# LKS32MC08x register map
Vendor: Linko Ltd.; Series: LKS32MC08x; File version: 1.0
CPU: CM0 r1p0, little endian, MPU, no FPU, 3 interrupt priority bits
Registers are 32-bit, read-write, reset 0x0 unless marked. A register's access mark holds for its fields unless they carry their own. Offsets are from the block's base; [hi:lo] are bit positions; {n}, {i} and the like mark numbered series; 'fields as' and 'values as' point back to an identical list.

## MCPWM — MCPWM registers
Base 0x40011C00
0x00 MCPWM_TH00 (reset mask 0xFFFF) — MCPWM0 CH0 P 16-bit Signed Compare Threshold Value
0x04 MCPWM_TH01 (reset mask 0xFFFF) — MCPWM0 CH0 N 16-bit Signed Compare Threshold Value
0x08 MCPWM_TH10 (reset mask 0xFFFF) — MCPWM1 CH1 P 16-bit Signed Compare Threshold Value
0x0C MCPWM_TH11 (reset mask 0xFFFF) — MCPWM1 CH1 N 16-bit Signed Compare Threshold Value
0x10 MCPWM_TH20 (reset mask 0xFFFF) — MCPWM2 CH2 P 16-bit Signed Compare Threshold Value
0x14 MCPWM_TH21 (reset mask 0xFFFF) — MCPWM2 CH2 N 16-bit Signed Compare Threshold Value
0x18 MCPWM_TH30 (reset mask 0xFFFF) — MCPWM3 CH3 P 16-bit Signed Compare Threshold Value
0x1C MCPWM_TH31 (reset mask 0xFFFF) — MCPWM3 CH3 N 16-bit Signed Compare Threshold Value
{0x20+4i} MCPWM_TMR{i} (reset mask 0xFFFF) (i=0..3) — ADC Sample Timer, 16-bit Signed Compare Threshold Value {i}
0x30 MCPWM_TH (reset mask 0x7FFF) — MCPWM Base Counter 15-bit Unsigned Threshold Value
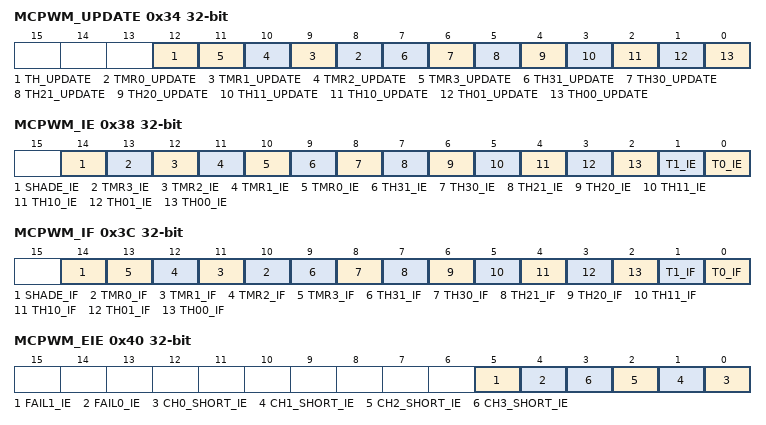
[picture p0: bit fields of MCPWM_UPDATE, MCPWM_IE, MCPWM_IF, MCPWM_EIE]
0x34 MCPWM_UPDATE wo — Mask Registers Manual Reload Configuration
  [12] TH_UPDATE — Write 1 to Trig TH Update Forcely
    0=Disabled (No Update); 1=Enabled (Trig TH Update)
  [n+8] TMR{n}_UPDATE (n=0..3) — Write 1 to Trig TMR{n} Update Forcely
    0=Disabled (No Update); 1=Enabled (Trig TMR{n} Update)
  [7] TH31_UPDATE — Write 1 to Trig TH31 Update Forcely
    0=Disabled (No Update); 1=Enabled (Trig TH31 Update)
  [6] TH30_UPDATE — Write 1 to Trig TH30 Update Forcely
    0=Disabled (No Update); 1=Enabled (Trig TH30 Update)
  [5] TH21_UPDATE — Write 1 to Trig TH21 Update Forcely
    0=Disabled (No Update); 1=Enabled (Trig TH21 Update)
  [4] TH20_UPDATE — Write 1 to Trig TH20 Update Forcely
    0=Disabled (No Update); 1=Enabled (Trig TH20 Update)
  [3] TH11_UPDATE — Write 1 to Trig TH11 Update Forcely
    0=Disabled (No Update); 1=Enabled (Trig TH11 Update)
  [2] TH10_UPDATE — Write 1 to Trig TH10 Update Forcely
    0=Disabled (No Update); 1=Enabled (Trig TH10 Update)
  [1] TH01_UPDATE — Write 1 to Trig TH01 Update Forcely
    0=Disabled (No Update); 1=Enabled (Trig TH01 Update)
  [0] TH00_UPDATE — Write 1 to Trig TH00 Update Forcely
    0=Disabled (No Update); 1=Enabled (Trig TH00 Update)
0x38 MCPWM_IE — Interrupt Sources Enable
  [14] SHADE_IE — Shade Register Update Interrupt Enable
    0=Disabled (Shade Register Event will not generate interrupt); 1=Enabled (Shade Register Event will generate interrupt)
  [13] TMR3_IE — Timer is equal to TMR3 Interrupt Enable
    0=Disabled (TMR3 Event will not generate interrupt); 1=Enabled (TMR3 Event will generate interrupt)
  [12] TMR2_IE — Timer is equal to TMR2 Interrupt
    0=Disabled (TMR2 Event will not generate interrupt); 1=Enabled (TMR2 Event will generate interrupt)
  [11] TMR1_IE — Timer is equal to TMR1 Interrupt
    0=Disabled (TMR1 Event will not generate interrupt); 1=Enabled (TMR1 Event will generate interrupt)
  [10] TMR0_IE — TMR0 Event,Timer is equal to TMR0 Interrupt
    0=Disabled (TMR0 Event will not generate interrupt); 1=Enabled (TMR0 Event will generate interrupt)
  [9] TH31_IE — Timer is equal to TH31 Interrupt
    0=Disabled (TH31 Event will not generate interrupt); 1=Enabled (TH31 Event will generate interrupt)
  [8] TH30_IE — TH30 Event,Timer is equal to TH30 Interrupt
    0=Disabled (TH30 Event will not generate interrupt); 1=Enabled (TH30 Event will generate interrupt)
  [7] TH21_IE — TH21 Event,Timer is equal to TH21 Interrupt
    0=Disabled (TH21 Event will not generate interrupt); 1=Enabled (TH21 Event will generate interrupt)
  [6] TH20_IE — Timer is equal to TH20 Interrupt
    0=Disabled (TH20 Event will not generate interrupt); 1=Enabled (TH20 Event will generate interrupt)
  [5] TH11_IE — TH11 Event,Timer is equal to TH11 Interrupt
    0=Disabled (TH11 Event will not generate interrupt); 1=Enabled (TH11 Event will generate interrupt)
  [4] TH10_IE — Timer is equal to TH10 Interrupt
    0=Disabled (TH10 Event will not generate interrupt); 1=Enabled (TH10 Event will generate interrupt)
  [3] TH01_IE — TH01 Event,Timer is equal to TH01 Interrupt
    0=Disabled (TH01 Event will not generate interrupt); 1=Enabled (TH01 Event will generate interrupt)
  [2] TH00_IE — Timer is equal to TH00 Interrupt
    0=Disabled (TH00 Event will not generate interrupt); 1=Enabled (TH00 Event will generate interrupt)
  [1] T1_IE — Timer is equal to 0 Interrupt
    0=Disabled (T1 Event will not generate interrupt); 1=Enabled (T1 Event will generate interrupt)
  [0] T0_IE — Timer Return to -TH Interrupt
    0=Disabled (T0 Event will not generate interrupt); 1=Enabled (T0 Event will generate interrupt)
0x3C MCPWM_IF — Interrupt Flags Write Clear
  [14] SHADE_IF — Shade Register Update Interrupt Flag
    0=Clear (Shade Register Interrupt Flag not set); 1=Set (Shade Register Interrupt Flag set)
  [n+10] TMR{n}_IF (n=0..3) — TMR{n} Interrupt Flag,Timer is equal to TMR{n}
    0=Clear (TMR{n} Interrupt Flag not set); 1=Set (TMR{n} Interrupt Flag set)
  [9] TH31_IF — TH31 Interrupt Flag,Timer is equal to TH31
    0=Clear (TH31 Interrupt Flag not set); 1=Set (TH31 Interrupt Flag set)
  [8] TH30_IF — TH30 Interrupt Flag,Timer is equal to TH30
    0=Clear (TH30 Interrupt Flag not set); 1=Set (TH30 Interrupt Flag set)
  [7] TH21_IF — TH21 Interrupt Flag,Timer is equal to TH21
    0=Clear (TH21 Interrupt Flag not set); 1=Set (TH21 Interrupt Flag set)
  [6] TH20_IF — TH20 Interrupt Flag,Timer is equal to TH20
    0=Clear (TH20 Interrupt Flag not set); 1=Set (TH20 Interrupt Flag set)
  [5] TH11_IF — TH11 Interrupt Flag,Timer is equal to TH11
    0=Clear (TH11 Interrupt Flag not set); 1=Set (TH11 Interrupt Flag set)
  [4] TH10_IF — TH10 Interrupt Flag,Timer is equal to TH10
    0=Clear (TH10 Interrupt Flag not set); 1=Set (TH10 Interrupt Flag set)
  [3] TH01_IF — TH01 Interrupt Flag,Timer is equal to TH01
    0=Clear (TH01 Interrupt Flag not set); 1=Set (TH01 Interrupt Flag set)
  [2] TH00_IF — TH00 Interrupt Flag,Timer is equal to TH00
    0=Clear (TH00 Interrupt Flag not set); 1=Set (TH00 Interrupt Flag set)
  [1] T1_IF — T1 Interrupt Flag,Timer Return to -TH
    0=Clear (T1 Interrupt Flag not set); 1=Set (T1 Interrupt Flag set)
  [0] T0_IF — T0 Interrupt Flag,Timer Return to -TH
    0=Clear (T0 Interrupt Flag not set); 1=Set (T0 Interrupt Flag set)
0x40 MCPWM_EIE — Error Interrupt Sources Enable
  [5] FAIL1_IE — FAIL1 Interrupt
    0=Disabled (FAIL1 will not generate interrupt); 1=Enabled (FAIL1 will generate interrupt)
  [4] FAIL0_IE — FAIL0 Interrupt
    0=Disabled (FAIL0 will not generate interrupt); 1=Enabled (FAIL0 will generate interrupt)
  [n] CH{n}_SHORT_IE (n=0..3) — CH{n} Short Interrupt
    0=Disabled (CH{n} Short will not generate interrupt); 1=Enabled (CH{n} Short will generate interrupt)
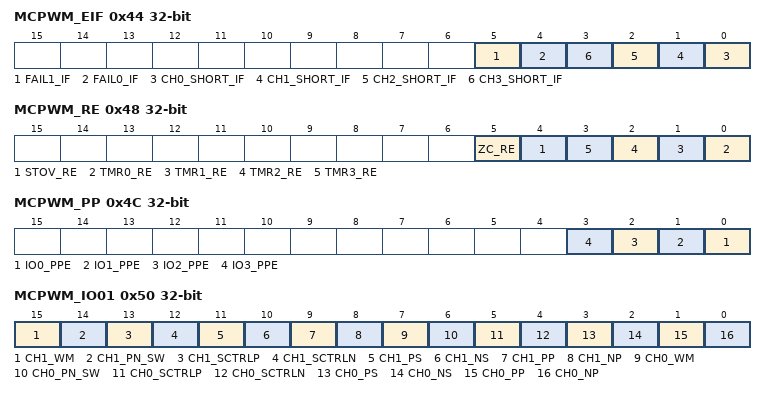
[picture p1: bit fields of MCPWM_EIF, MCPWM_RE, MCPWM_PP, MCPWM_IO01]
0x44 MCPWM_EIF — Error Interrupt Flags Write Clear
  [5] FAIL1_IF — FAIL1 Interrupt Flag
    0=Clear (FAIL1 flag not set); 1=Set (FAIL1 flag set)
  [4] FAIL0_IF — FAIL0 Interrupt Flag
    0=Clear (FAIL0 flag not set); 1=Set (FAIL0 flag set)
  [n] CH{n}_SHORT_IF (n=0..3) — CH{n} Short Interrupt Flag
    0=Clear (CH{n} Short flag not set); 1=Set (CH{n} Short flag set)
0x48 MCPWM_RE — DMA request enable
  [5] ZC_RE — Zero Crossing Event will request DMA or not
    0=Disabled (Zero Crossing Event DMA request is disabled); 1=Enabled (Zero Crossing Event DMA request is enabled)
  [4] STOV_RE — Counter Start Over Event will request DMA or not
    0=Disabled (Conter start over event DMA request is disabled); 1=Enabled (Conter start over event DMA request is enabled)
  [n] TMR{n}_RE (n=0..3) — ADC trigger {n} will request DMA or not
    0=Disabled (ADC trigger {n} DMA request is disabled); 1=Enabled (ADC trigger {n} DMA request is enabled)
0x4C MCPWM_PP — Push-Pull configuration
  [n] IO{n}_PPE (n=0..3) — IO{n} Push-Pull mode enable
    0=Disabled (IO{n} Push-Pull mode is disabled); 1=Enabled (IO{n} Push-Pull mode is enabled)
0x50 MCPWM_IO01 — Channel 0/1 Setting
  [15] CH1_WM — Channel_1 WorkMode
    0=CMP (Complement Mode); 1=Edge Mode
  [14] CH1_PN_SW — Channel_1 P/N Switch
    0=ORG (Not Switch); 1=SWAP (Switch)
  [13] CH1_SCTRLP — Channel_1 SoftCtrlP
    0=L (P set to 0); 1=H (P set to 1)
  [12] CH1_SCTRLN — Channel_1 SoftCtrlN
    0=L (N set to 0); 1=H (N set to 1)
  [11] CH1_PS — Channel_1 P Source
    0=TIMER (From Timer); 1=BIT13 (From Bit13)
  [10] CH1_NS — Channel_1 N Source
    0=TIMER (From Timer); 1=BIT12 (From Bit12)
  [9] CH1_PP — Channel_1 P Polarity
    0=Disabled (P Not Inverted); 1=Enabled (P Inverted)
  [8] CH1_NP — Channel_1 N Polarity
    0=Disabled (N Not Inverted); 1=Enabled (N Inverted)
  [7] CH0_WM — Channel_0 WorkMode
    0=CMP (Complement Mode); 1=Edge Mode
  [6] CH0_PN_SW — Channel_0 P/N Switch
    0=ORG (Not Switch); 1=SWAP (Switch)
  [5] CH0_SCTRLP — Channel_0 SoftCtrlP
    0=L (P set to 0); 1=H (P set to 1)
  [4] CH0_SCTRLN — Channel_0 SoftCtrlN
    0=L (N set to 0); 1=H (N set to 1)
  [3] CH0_PS — Channel_0 P Source
    0=TIMER (From Timer); 1=BIT13 (From Bit13)
  [2] CH0_NS — Channel_0 N Source
    0=TIMER (From Timer); 1=BIT12 (From Bit12)
  [1] CH0_PP — Channel_0 P Polarity
    0=Disabled (P Not Inverted); 1=Enabled (P Inverted)
  [0] CH0_NP — Channel_0 N Polarity
    0=Disabled (N Not Inverted); 1=Enabled (N Inverted)
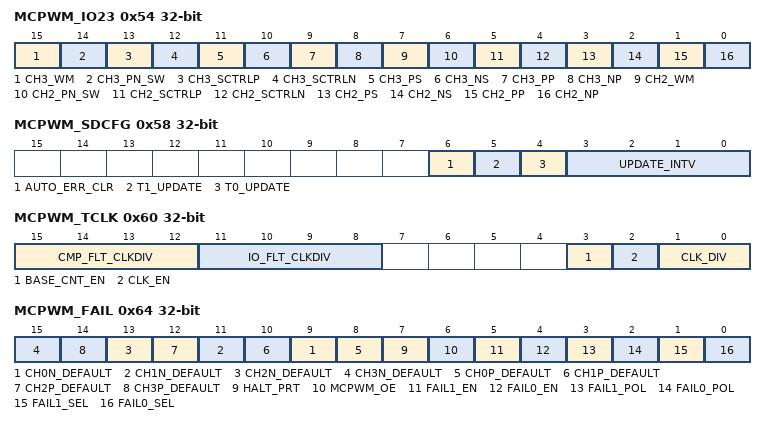
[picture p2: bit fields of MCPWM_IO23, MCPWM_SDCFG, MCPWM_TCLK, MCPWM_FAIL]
0x54 MCPWM_IO23 — Channel 2/3 Setting
  [15] CH3_WM — Channel_3 WorkMode
    0=CMP (Complement Mode); 1=Edge Mode
  [14] CH3_PN_SW — Channel_3 P/N Switch
    0=ORG (Not Switch); 1=SWAP (Switch)
  [13] CH3_SCTRLP — Channel_3 SoftCtrlP
    0=L (P set to 0); 1=H (P set to 1)
  [12] CH3_SCTRLN — Channel_3 SoftCtrlN
    0=L (N set to 0); 1=H (N set to 1)
  [11] CH3_PS — Channel_3 P Source
    0=TIMER (From Timer); 1=BIT13 (From Bit13)
  [10] CH3_NS — Channel_3 N Source
    0=TIMER (From Timer); 1=BIT12 (From Bit12)
  [9] CH3_PP — Channel_3 P Polarity
    0=Disabled (P Not Inverted); 1=Enabled (P Inverted)
  [8] CH3_NP — Channel_3 N Polarity
    0=Disabled (N Not Inverted); 1=Enabled (N Inverted)
  [7] CH2_WM — Channel_2 WorkMode
    0=CMP (Complement Mode); 1=Edge Mode
  [6] CH2_PN_SW — Channel_2 P/N Switch
    0=ORG (Not Switch); 1=SWAP (Switch)
  [5] CH2_SCTRLP — Channel_2 SoftCtrlP
    0=L (P set to 0); 1=H (P set to 1)
  [4] CH2_SCTRLN — Channel_2 SoftCtrlN
    0=L (N set to 0); 1=H (N set to 1)
  [3] CH2_PS — Channel_2 P Source
    0=TIMER (From Timer); 1=BIT13 (From Bit13)
  [2] CH2_NS — Channel_2 N Source
    0=TIMER (From Timer); 1=BIT12 (From Bit12)
  [1] CH2_PP — Channel_2 P Polarity
    0=Disabled (P Not Inverted); 1=Enabled (P Inverted)
  [0] CH2_NP — Channel_2 N Polarity
    0=Disabled (N Not Inverted); 1=Enabled (N Inverted)
0x58 MCPWM_SDCFG (reset mask 0x3F) — Mask Registers Reload Configuration
  [6] AUTO_ERR_CLR — Whether to clear MOE upon update events
    0=Disabled (Not clear); 1=Enabled (Clear)
  [5] T1_UPDATE — Update shadow registers @ T1 event
    0=Disabled (T1 Event will not update shadow registers); 1=Enabled (T1 Event will update shadow registers)
  [4] T0_UPDATE — Update shadow registers @ T0 event
    0=Disabled (T0 Event will not update shadow registers); 1=Enabled (T0 Event will update shadow registers)
  [3:0] UPDATE_INTV — Mask Registers Auto Update Interval, Range From 1 To 16. T1/T2 Events Can Accumulate Interval Source Register
    {v}=Value (The Total Number of T1 and T2 Event is {v+1}) (v=0..15)
0x60 MCPWM_TCLK — MCPWM Clock Configuration Register
  [15:12] CMP_FLT_CLKDIV — Clock Source is System Clock, Divide Range is 1 to 16
    {v}=Value (Divide by {v+1}) (v=0..15)
  [11:8] IO_FLT_CLKDIV — Clock Source is System Clock, Divide Range is 1 to 16
    {v}=Value (Divide by {v+1}) (v=0..15)
  [3] BASE_CNT_EN — Base Counter Enable or Not
    0=Disabled (Disable Base Counter); 1=Enabled (Enable Base Counter)
  [2] CLK_EN — Module Clock Enable or Not
    0=Disabled (Disable Module Clock); 1=Enabled (Enable Module Clock)
  [1:0] CLK_DIV — Module Clock Divider Setting, Clock Source is System Clock
    0=Value (Divide by 1); 1=Value (Divide by 2); 2=Value (Divide by 4); 3=Value (Divide by 8)
0x64 MCPWM_FAIL — MCPWM IO Short Control Register
  [2n+9] CH{n}N_DEFAULT (n=0..3) — CH{n}_N Default Value
    0=Value (Default 0); 1=Value (Default 1)
  [2n+8] CH{n}P_DEFAULT (n=0..3) — CH{n}_P Default Value
    0=Value (Default 0); 1=Value (Default 1)
  [7] HALT_PRT — MCU in Debug Mode(Halted by Debug), MCPWM Close or Not
    0=Value (MCPWM is Closed for Protection); 1=Value (MCPWM Keeps Current State)
  [6] MCPWM_OE — MCPWM Output Enable
    0=Disabled (MCPWM Output Disabled. If MCPWM_EIF[5:0] Events Happened, Disable This Bit.); 1=Enabled (MCPWM Output Enabled)
  [5] FAIL1_EN — FAIL 1 Short Protect Enable or Not
    0=Disabled (Disable Short Protect); 1=Enabled (Enable Short Protect)
  [4] FAIL0_EN — FAIL 0 Short Protect Enable or Not
    values as FAIL1_EN
  [3] FAIL1_POL — IO 1 Active Setting
    0=Value (High Level Active); 1=Value (Low Level Active)
  [2] FAIL0_POL — IO 0 Active Setting
    0=Value (High Level Active); 1=Value (Low Level Active)
  [1] FAIL1_SEL — Select from CMP1 or IO 1
    0=Value (Select IO 1); 1=Value (Select CMP 1)
  [0] FAIL0_SEL — Select from CMP0 or IO 0
    0=Value (Select IO 0); 1=Value (Select CMP 0)
0x74 MCPWM_PRT wo (reset mask 0xFFFF) — MCPWM Register Protection.Write 0xDEAD to unlock Protect
0x78 MCPWM_CNT (reset mask 0xFFFF) — MCPWM Base Counter Value
0x80 MCPWM_DTH00 (reset mask 0xFFFF) — Channel 0 N Dead Zone Control Register, 10-bit Unsigned
0x84 MCPWM_DTH01 (reset mask 0xFFFF) — Channel 0 P Dead Zone Control Register, 10-bit Unsigned
0x88 MCPWM_DTH10 (reset mask 0xFFFF) — Channel 1 N Dead Zone Control Register, 10-bit Unsigned
0x8C MCPWM_DTH11 (reset mask 0xFFFF) — Channel 1 P Dead Zone Control Register, 10-bit Unsigned
0x90 MCPWM_DTH20 (reset mask 0xFFFF) — Channel 2 N Dead Zone Control Register, 10-bit Unsigned
0x94 MCPWM_DTH21 (reset mask 0xFFFF) — Channel 2 P Dead Zone Control Register, 10-bit Unsigned
0x98 MCPWM_DTH30 (reset mask 0xFFFF) — Channel 3 N Dead Zone Control Register, 10-bit Unsigned
0x9C MCPWM_DTH31 (reset mask 0xFFFF) — Channel 3 P Dead Zone Control Register, 10-bit Unsigned
